AUTOSAR XML (schema 314)
package /ComponentType
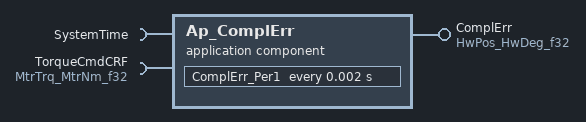
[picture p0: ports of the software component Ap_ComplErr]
  application software component type Ap_ComplErr
    provide port ComplErr: unqueued-sender-com-spec{data-element=HwDeg_f32, can-invalidate=false, init-value=D_ZERO_ULS_F32}, provided-interface=HwPos_HwDeg_f32
    require port SystemTime: required-interface=SystemTime
      required-com-specs:
        DtrmnElapsedTime_mS_u16
        DtrmnElapsedTime_mS_u32
        DtrmnElapsedTime_uS_u16
        DtrmnElapsedTime_uS_u32
        GetSystemTime_mS_u32
        GetSystemTime_uS_u32
    require port TorqueCmdCRF: unqueued-receiver-com-spec{data-element=MtrNm_f32, init-value=D_ZERO_ULS_F32}, required-interface=MtrTrq_MtrNm_f32
  internal behavior Ap_ComplErr_InternalBehavior: component=Ap_ComplErr
    timing event TMT_ComplErr_Per1: start-on-event=ComplErr_Per1, period=0.002
    port-api-options:
      enable-take-address=false, indirect-api=false, port=ComplErr
      enable-take-address=false, indirect-api=false, port=SystemTime
      enable-take-address=false, indirect-api=false, port=TorqueCmdCRF
    runnable ComplErr_Per1
      data read access READ_TorqueCmdCRF_MtrNm_f32: data-element=TorqueCmdCRF.MtrNm_f32
      data write access WRITE_ComplErr_HwDeg_f32: data-element=ComplErr.HwDeg_f32
  swc implementation Ap_ComplErr_Implementation: behavior=Ap_ComplErr_InternalBehavior
    code-descriptors:
      code Code: type=SRC
